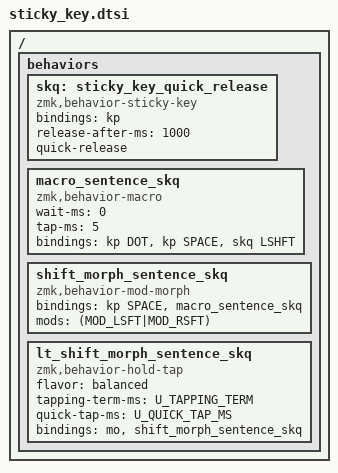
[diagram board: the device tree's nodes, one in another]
// Copyright 2022 Lukas Kucera
// https://github.com/kucera-lukas/zmk-config

#include <behaviors.dtsi>
#include <dt-bindings/zmk/keys.h>

/ {
  behaviors {
    skq: sticky_key_quick_release {
      compatible = "zmk,behavior-sticky-key";
      #binding-cells = <1>;
      bindings = <&kp>;
      release-after-ms = <1000>; // release after 1s
      quick-release;  // no double capitalization when rolling keys
    };

    macro_sentence_skq: macro_sentence_skq {
      compatible = "zmk,behavior-macro";
      #binding-cells = <0>;
      wait-ms = <0>;
      tap-ms = <5>;
      bindings = <&kp DOT &kp SPACE &skq LSHFT>;
    };

    shift_morph_sentence_skq: shift_morph_sentence_skq {
      compatible = "zmk,behavior-mod-morph";
      #binding-cells = <0>;
      bindings = <&kp SPACE>, <&macro_sentence_skq>;
      mods = <(MOD_LSFT|MOD_RSFT)>;
    };

    lt_shift_morph_sentence_skq: lt_shift_morph_sentence_skq {
      compatible = "zmk,behavior-hold-tap";
      #binding-cells = <2>;
      flavor = "balanced";
      tapping-term-ms = <U_TAPPING_TERM>;
      quick-tap-ms = <U_QUICK_TAP_MS>;
      bindings = <&mo>, <&shift_morph_sentence_skq>;
    };
  };
};
